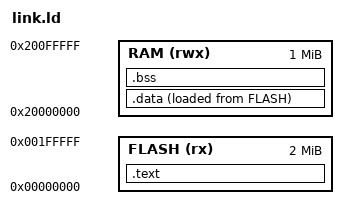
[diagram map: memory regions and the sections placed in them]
ENTRY(Reset_Handler)

MEMORY
{
    FLASH (rx)  : ORIGIN = 0x00000000, LENGTH = 2M
    RAM   (rwx) : ORIGIN = 0x20000000, LENGTH = 1M
}

SECTIONS
{
    .text :
    {
        KEEP(*(.vectors))
        *(.text*)
        *(.rodata*)
    } > FLASH

    .data :
    {
        *(.data*)
    } > RAM AT > FLASH

    .bss :
    {
        *(.bss*)
        *(COMMON)
    } > RAM

    . = ALIGN(8);
    __stack_bottom = .;
    . = . + 0x4000;
    __stack_top = .;
}
